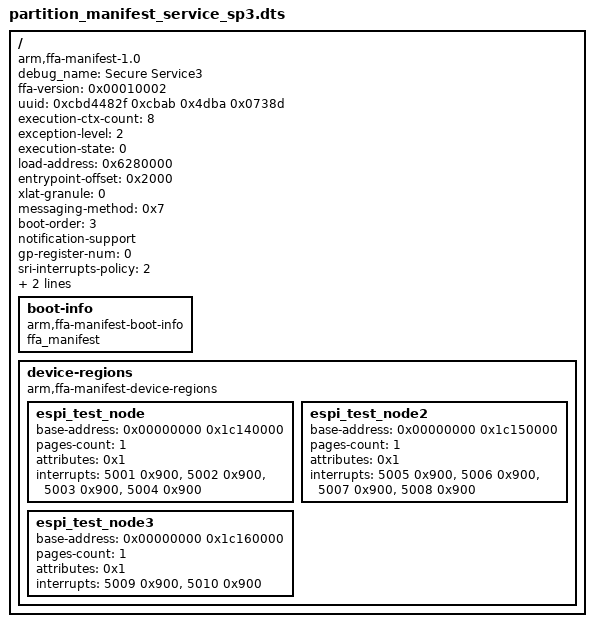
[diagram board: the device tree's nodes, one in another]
/*
 * Copyright 2022 The Hafnium Authors.
 *
 * Use of this source code is governed by a BSD-style
 * license that can be found in the LICENSE file or at
 * https://opensource.org/licenses/BSD-3-Clause.
 */

/dts-v1/;

/ {
	compatible = "arm,ffa-manifest-1.0";
	debug_name = "Secure Service3";

	/* Properties */
	ffa-version = <0x00010002>; /* 31:16 - Major, 15:0 - Minor */
        uuid = <0xcbd4482f 0xcbab 0x4dba 0x0738d>;
	execution-ctx-count = <8>;
	exception-level = <2>; /* S-EL1 */
	execution-state = <0>; /* AARCH64 */
	load-address = <0x6280000>;
	entrypoint-offset = <0x2000>;
	xlat-granule = <0>; /* 4KiB */
	messaging-method = <0x7>; /* Supports direct and indirect requests. */
	boot-order = <3>;
	notification-support; /* Receipt of notifications. */
	gp-register-num = <0>;

	/*
	 * Trigger SRI when getting into the waiting state.
	 */
	sri-interrupts-policy = <2>;

	ns-interrupts-action = <1>; /* Managed exit is supported. */
	managed-exit-virq;

	/* Boot Info */
	boot-info {
		compatible = "arm,ffa-manifest-boot-info";
		ffa_manifest;
	};

	device-regions {
		compatible = "arm,ffa-manifest-device-regions";

		espi_test_node {
			/*
			 * A dummy device region node representing a fake
			 * peripheral. Explicitly used to specify properties of
			 * eSPIs, used for interrupt tests.
			 * All the properties below except `interrupts` are irrelevant.
			 */
			base-address = <0x00000000 0x1c140000>;
			pages-count = <1>; /* One 4KB page */
			attributes = <0x1>; /* read-only */
			interrupts = <5001 0x900>, /* Attributes = Secure SPI. */
				     <5002 0x900>,
				     <5003 0x900>,
				     <5004 0x900>;
		};

		espi_test_node2 {
			/*
			 * A dummy device region node representing a fake
			 * peripheral. Explicitly used to specify properties of
			 * eSPIs, used for the back to back and burst interrupt tests.
			 * All the properties below except `interrupts` are irrelevant.
			 */
			base-address = <0x00000000 0x1c150000>;
			pages-count = <1>; /* One 4KB page */
			attributes = <0x1>; /* read-only */
			interrupts = <5005 0x900>, /* Attributes = Secure SPI. */
				     <5006 0x900>,
				     <5007 0x900>,
				     <5008 0x900>;
		};

		espi_test_node3 {
			/*
			 * A dummy device region node representing a fake
			 * peripheral. Explicitly used to specify properties of
			 * eSPIs, used for the back to back and burst interrupt tests.
			 * All the properties below except `interrupts` are irrelevant.
			 */
			base-address = <0x00000000 0x1c160000>;
			pages-count = <1>; /* One 4KB page */
			attributes = <0x1>; /* read-only */
			interrupts = <5009 0x900>, /* Attributes = Secure SPI. */
				     <5010 0x900>;
		};


	};

};
